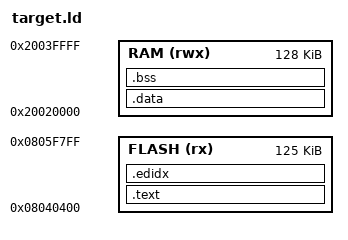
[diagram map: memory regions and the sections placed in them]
/* target.ld
 *
 * Copyright (C) 2026 wolfSSL Inc.
 *
 * This file is part of wolfBoot.
 *
 * wolfBoot is free software; you can redistribute it and/or modify
 * it under the terms of the GNU General Public License as published by
 * the Free Software Foundation; either version 3 of the License, or
 * (at your option) any later version.
 *
 * wolfBoot is distributed in the hope that it will be useful,
 * but WITHOUT ANY WARRANTY; without even the implied warranty of
 * MERCHANTABILITY or FITNESS FOR A PARTICULAR PURPOSE.  See the
 * GNU General Public License for more details.
 *
 * You should have received a copy of the GNU General Public License
 * along with this program; if not, write to the Free Software
 * Foundation, Inc., 51 Franklin Street, Fifth Floor, Boston, MA 02110-1335, USA
 */

MEMORY
{
    FLASH (rx) : ORIGIN = 0x8040400, LENGTH = 0x1f400
    RAM (rwx) : ORIGIN = 0x20020000, LENGTH = 0x20000
}

SECTIONS
{
    .text :
    {
        _start_text = .;
        . = ALIGN(8);
        KEEP(*(.isr_vector))
        . = ALIGN(8);
        *(.init)
        *(.fini)
        *(.text*)
        *(.rodata*)
        . = ALIGN(8);
        _end_text = .;
    } > FLASH

    .edidx :
    {
        . = ALIGN(4);
        *(.ARM.exidx*)
    } > FLASH

    _stored_data = .;

    .data : AT (_stored_data)
    {
        _start_data = .;
        KEEP(*(.data*))
        . = ALIGN(8);
        KEEP(*(.ramcode))
        . = ALIGN(8);
        _end_data = .;
    } > RAM

    .bss :
    {
        _start_bss = .;
        *(.bss*)
        *(COMMON)
        . = ALIGN(8);
        _end_bss = .;
        _end = .;
    } > RAM
}

PROVIDE(_start_heap = _end);
PROVIDE(_end_stack  = ORIGIN(RAM) + LENGTH(RAM));

/* Emu app startup expects these symbols. */
_estack = _end_stack;
_sidata = _stored_data;
_sdata = _start_data;
_edata = _end_data;
_sbss = _start_bss;
_ebss = _end_bss;
